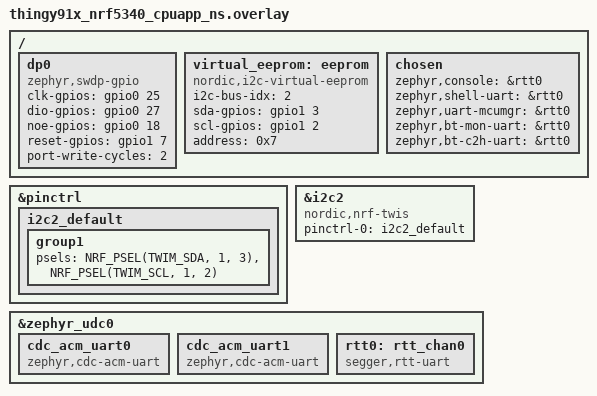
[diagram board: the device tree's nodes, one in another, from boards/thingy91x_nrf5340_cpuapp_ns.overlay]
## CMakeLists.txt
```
#
# Copyright (c) 2020 Nordic Semiconductor
#
# SPDX-License-Identifier: LicenseRef-Nordic-5-Clause
#

cmake_minimum_required(VERSION 3.20.0)

find_package(Zephyr REQUIRED HINTS $ENV{ZEPHYR_BASE})
find_package(Git)
project(NONE)

# NORDIC SDK APP START
target_sources(app PRIVATE src/main.c)
# NORDIC SDK APP END

# Generate a C header file with the readme text as a string variable
set(OUTPUT_README_HEADER_FILE "${CMAKE_BINARY_DIR}/generated/readme/readme.h")
set(INPUT_README_FILE ${CMAKE_SOURCE_DIR}/boards/${BOARD}_readme.txt)
if(NOT EXISTS ${INPUT_README_FILE})
message(WARNING "${INPUT_README_FILE} does not exist")
set(INPUT_README_FILE ${CMAKE_SOURCE_DIR}/README_TEMPLATE.txt)
endif()
file(READ ${INPUT_README_FILE} README_CONTENT)
if(GIT_FOUND)
  execute_process(
        COMMAND ${GIT_EXECUTABLE} rev-parse --short HEAD
        WORKING_DIRECTORY ${CMAKE_SOURCE_DIR}
        OUTPUT_VARIABLE GIT_HASH
        OUTPUT_STRIP_TRAILING_WHITESPACE
  )
  string(TIMESTAMP CURRENT_DATE "%Y-%m-%d")
  string(APPEND README_CONTENT "\nFirmware version: ${GIT_HASH} (${CURRENT_DATE})")
endif()
string(REPLACE "\"" "\\\"" README_CONTENT "${README_CONTENT}")
string(REPLACE "\n" "\\n\"\n\"" README_CONTENT "${README_CONTENT}")
file(WRITE ${OUTPUT_README_HEADER_FILE} "const char* file_contents = \"${README_CONTENT}\";\n\n")


# Include application events and disk files
zephyr_library_include_directories(
  src/events
  ${NRF_DIR}/samples/dap/src
  ${CMAKE_BINARY_DIR}/generated/readme
  )

# Application sources
add_subdirectory(src/disk)
add_subdirectory(src/events)
add_subdirectory(src/modules)
```

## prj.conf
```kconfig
# General
CONFIG_REBOOT=y
CONFIG_HEAP_MEM_POOL_SIZE=8192
CONFIG_SYSTEM_WORKQUEUE_STACK_SIZE=2048
CONFIG_MAIN_STACK_SIZE=2048
CONFIG_GPIO=y
CONFIG_POLL=y
CONFIG_BOOTLOADER_MCUBOOT=y
CONFIG_APP_EVENT_MANAGER=y
CONFIG_SPEED_OPTIMIZATIONS=y
CONFIG_PM_DEVICE=y

# Features
CONFIG_BRIDGE_CDC_ENABLE=y
CONFIG_BRIDGE_MSC_ENABLE=y
CONFIG_BRIDGE_BLE_ENABLE=y

 # USB
CONFIG_USB_DEVICE_STACK=y
CONFIG_USB_DEVICE_REMOTE_WAKEUP=n
CONFIG_USB_DEVICE_MANUFACTURER="Nordic Semiconductor"
CONFIG_USB_DEVICE_PRODUCT="Thingy:91 UART"
CONFIG_USB_DEVICE_VID=0x1915
CONFIG_USB_DEVICE_PID=0x9100
CONFIG_USB_DEVICE_SN="THINGY91 12PLACEHLDRS" # This is overridden at runtime
CONFIG_USB_COMPOSITE_DEVICE=y
CONFIG_USB_CDC_ACM_RINGBUF_SIZE=16384

# Disk and file system
CONFIG_DISK_ACCESS=y
CONFIG_DISK_DRIVER_RAM=y
CONFIG_DISK_RAM_VOLUME_SIZE=64
CONFIG_FILE_SYSTEM=y
CONFIG_FAT_FILESYSTEM_ELM=y
CONFIG_FS_FATFS_LFN=y

# Settings
CONFIG_FCB=y
CONFIG_SETTINGS=y
CONFIG_SETTINGS_FCB=y
CONFIG_FLASH=y
CONFIG_FLASH_PAGE_LAYOUT=y
CONFIG_FLASH_MAP=y
CONFIG_MPU_ALLOW_FLASH_WRITE=y

# Logging
CONFIG_LOG=y
CONFIG_USE_SEGGER_RTT=y
CONFIG_LOG_BACKEND_RTT=y
CONFIG_LOG_BACKEND_RTT_MODE_DROP=y

# Event logs
CONFIG_BRIDGE_LOG_MODULE_STATE_EVENT=n
CONFIG_BRIDGE_LOG_UART_DATA_EVENT=n
CONFIG_BRIDGE_LOG_CDC_DATA_EVENT=n
CONFIG_BRIDGE_LOG_BLE_DATA_EVENT=n
CONFIG_BRIDGE_LOG_BLE_CTRL_EVENT=n
CONFIG_BRIDGE_LOG_PEER_CONN_EVENT=n
CONFIG_BRIDGE_LOG_FS_EVENT=n
CONFIG_BRIDGE_LOG_POWER_DOWN_EVENT=n

 # UART
CONFIG_SERIAL=y
CONFIG_UART_INTERRUPT_DRIVEN=y
CONFIG_UART_0_INTERRUPT_DRIVEN=n
CONFIG_UART_1_INTERRUPT_DRIVEN=n
CONFIG_UART_LINE_CTRL=y
CONFIG_UART_ASYNC_API=y
CONFIG_UART_0_ASYNC=y
CONFIG_UART_1_ASYNC=y
CONFIG_UART_0_NRF_HW_ASYNC=y
CONFIG_UART_1_NRF_HW_ASYNC=y
CONFIG_UART_0_NRF_HW_ASYNC_TIMER=1
CONFIG_UART_1_NRF_HW_ASYNC_TIMER=2
CONFIG_NRFX_UARTE0=y
CONFIG_NRFX_UARTE1=y
CONFIG_NRFX_TIMER1=y
CONFIG_NRFX_TIMER2=y
CONFIG_NRFX_PPI=y

CONFIG_HW_ID_LIBRARY=y
```

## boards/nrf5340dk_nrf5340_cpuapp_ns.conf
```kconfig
CONFIG_BT=y
CONFIG_BT_DEVICE_NAME="Thingy:91 X UART"
CONFIG_BT_DEVICE_NAME_DYNAMIC=y
CONFIG_BT_PERIPHERAL=y
CONFIG_BT_PERIPHERAL_PREF_MIN_INT=6
CONFIG_BT_PERIPHERAL_PREF_MAX_INT=16
CONFIG_BT_PERIPHERAL_PREF_LATENCY=0
CONFIG_BT_PERIPHERAL_PREF_TIMEOUT=400
CONFIG_BT_BONDABLE=n

CONFIG_BT_MAX_CONN=1
CONFIG_BT_AUTO_PHY_UPDATE=y
CONFIG_BT_DATA_LEN_UPDATE=y
CONFIG_BT_HCI_ACL_FLOW_CONTROL=y
CONFIG_BT_L2CAP_TX_MTU=247
CONFIG_BT_BUF_ACL_RX_SIZE=251
CONFIG_BT_NUS=y
CONFIG_BT_GATT_CLIENT=y
CONFIG_BT_SMP=y
CONFIG_BT_BUF_ACL_TX_COUNT=10
CONFIG_BT_BUF_ACL_TX_SIZE=251
CONFIG_BT_CTLR_DATA_LENGTH_MAX=251

CONFIG_USB_DEVICE_STACK=y
CONFIG_USB_DEVICE_BOS=y
CONFIG_USB_DEVICE_REMOTE_WAKEUP=n
CONFIG_USB_MAX_POWER=250
CONFIG_CMSIS_DAP_DEVICE_VENDOR="Nordic Semiconductor"
CONFIG_CMSIS_DAP_DEVICE_NAME="nrf9160_xxaa"

CONFIG_SERIAL=y
CONFIG_DAP=y
CONFIG_NRF_TRACE_PORT=y

CONFIG_DAP_LOG_LEVEL_DBG=y
CONFIG_DP_DRIVER_LOG_LEVEL_DBG=y
CONFIG_USB_MAX_NUM_TRANSFERS=8
```

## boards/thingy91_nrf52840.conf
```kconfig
CONFIG_BT=y
CONFIG_BT_DEVICE_NAME="Thingy:91 UART"
CONFIG_BT_DEVICE_NAME_DYNAMIC=y
CONFIG_BT_PERIPHERAL=y
CONFIG_BT_PERIPHERAL_PREF_MIN_INT=6
CONFIG_BT_PERIPHERAL_PREF_MAX_INT=16
CONFIG_BT_PERIPHERAL_PREF_LATENCY=0
CONFIG_BT_PERIPHERAL_PREF_TIMEOUT=400
CONFIG_BT_BONDABLE=n
CONFIG_BT_LL_SOFTDEVICE=y
CONFIG_BT_MAX_CONN=1
CONFIG_BT_AUTO_PHY_UPDATE=y
CONFIG_BT_DATA_LEN_UPDATE=y
CONFIG_BT_HCI_ACL_FLOW_CONTROL=y
CONFIG_BT_L2CAP_TX_MTU=247
CONFIG_BT_BUF_ACL_RX_SIZE=251
CONFIG_BT_NUS=y
CONFIG_BT_GATT_CLIENT=y
CONFIG_BT_SMP=y
CONFIG_BT_CTLR=y
CONFIG_BT_CTLR_RX_BUFFERS=10
CONFIG_BT_BUF_ACL_TX_COUNT=10
CONFIG_BT_BUF_ACL_TX_SIZE=251
CONFIG_BT_CTLR_DATA_LENGTH_MAX=251

CONFIG_USB_MAX_NUM_TRANSFERS=8
CONFIG_USB_DEVICE_STACK=y
CONFIG_USB_DEVICE_BOS=y
CONFIG_USB_DEVICE_REMOTE_WAKEUP=n
CONFIG_USB_MAX_POWER=250
CONFIG_CMSIS_DAP_DEVICE_VENDOR="Nordic Semiconductor"
CONFIG_CMSIS_DAP_DEVICE_NAME="nrf9160_xxaa"
CONFIG_SERIAL=y
CONFIG_DAP=y
```

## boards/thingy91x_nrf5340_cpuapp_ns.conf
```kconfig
CONFIG_BT=y
CONFIG_BT_DEVICE_NAME="Thingy:91 X UART"
CONFIG_BT_DEVICE_NAME_DYNAMIC=y
CONFIG_BT_PERIPHERAL=y
CONFIG_BT_PERIPHERAL_PREF_MIN_INT=6
CONFIG_BT_PERIPHERAL_PREF_MAX_INT=16
CONFIG_BT_PERIPHERAL_PREF_LATENCY=0
CONFIG_BT_PERIPHERAL_PREF_TIMEOUT=400
CONFIG_BT_BONDABLE=n

CONFIG_BT_MAX_CONN=1
CONFIG_BT_AUTO_PHY_UPDATE=y
CONFIG_BT_DATA_LEN_UPDATE=y
CONFIG_BT_HCI_ACL_FLOW_CONTROL=y
CONFIG_BT_L2CAP_TX_MTU=247
CONFIG_BT_BUF_ACL_RX_SIZE=251
CONFIG_BT_NUS=y
CONFIG_BT_GATT_CLIENT=y
CONFIG_BT_SMP=y
CONFIG_BT_BUF_ACL_TX_COUNT=10
CONFIG_BT_BUF_ACL_TX_SIZE=251
CONFIG_BT_CTLR_DATA_LENGTH_MAX=251

CONFIG_USB_MAX_NUM_TRANSFERS=8
CONFIG_USB_DEVICE_STACK=y
CONFIG_USB_DEVICE_BOS=y
CONFIG_USB_DEVICE_REMOTE_WAKEUP=n
CONFIG_USB_MAX_POWER=250
CONFIG_USB_DEVICE_PRODUCT="Thingy:91 X UART"
CONFIG_CMSIS_DAP_DEVICE_VENDOR="Nordic Semiconductor"
CONFIG_CMSIS_DAP_DEVICE_NAME="nrf9160_xxaa"
CONFIG_SERIAL=y
CONFIG_DAP=y

CONFIG_I2C=y
CONFIG_I2C_VIRTUAL_EEPROM_DRIVER=y
CONFIG_I2C_VIRTUAL_EEPROM_DRIVER_LOG_LEVEL_DBG=y
```

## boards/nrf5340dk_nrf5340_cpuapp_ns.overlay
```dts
/*
 * Copyright (c) 2023 Nordic Semiconductor ASA
 *
 * SPDX-License-Identifier: Apache-2.0
 */

&uart1 {
	status = "okay";
	current-speed = <115200>;
	pinctrl-0 = <&uart1_default>;
	pinctrl-1 = <&uart1_sleep>;
	pinctrl-names = "default", "sleep";
};

 
 / {
	dp0 {
		compatible = "zephyr,swdp-gpio";
		status = "okay";
		clk-gpios = <&gpio0 19 GPIO_ACTIVE_HIGH>;
		dio-gpios = <&gpio0 20 GPIO_ACTIVE_HIGH>;
		noe-gpios = <&gpio0 21 GPIO_ACTIVE_HIGH>;
		reset-gpios = <&gpio0 22 GPIO_ACTIVE_HIGH>;
		port-write-cycles = <2>;
	};
};


&zephyr_udc0 {
	cdc_acm_uart0: cdc_acm_uart0 {
		compatible = "zephyr,cdc-acm-uart";
	};

	cdc_acm_uart1: cdc_acm_uart1 {
		compatible = "zephyr,cdc-acm-uart";
	};

	rtt0: rtt_chan0 {
		compatible = "segger,rtt-uart";
		status = "okay";
	};
};

/ {
	chosen {
		zephyr,console = &rtt0;
		zephyr,shell-uart = &rtt0;
		zephyr,uart-mcumgr = &rtt0;
		zephyr,bt-mon-uart = &rtt0;
		zephyr,bt-c2h-uart = &rtt0;
	};
};
```

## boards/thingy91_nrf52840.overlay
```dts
/*
 * Copyright (c) 2023 Nordic Semiconductor ASA
 *
 * SPDX-License-Identifier: Apache-2.0
 */

 
/ {
	dp0 {
		compatible = "zephyr,swdp-gpio";
		status = "okay";
		clk-gpios = <&gpio1 5 GPIO_ACTIVE_HIGH>;
		dio-gpios = <&gpio0 14 GPIO_ACTIVE_HIGH>;
		noe-gpios = <&gpio0 17 GPIO_ACTIVE_HIGH>;
		port-write-cycles = <2>;
	};
};

&zephyr_udc0 {
	cdc_acm_uart0: cdc_acm_uart0 {
		compatible = "zephyr,cdc-acm-uart";
	};

	cdc_acm_uart1: cdc_acm_uart1 {
		compatible = "zephyr,cdc-acm-uart";
	};

	rtt0: rtt_chan0 {
		compatible = "segger,rtt-uart";
		status = "okay";
	};
};

/ {
	chosen {
		zephyr,console = &rtt0;
		zephyr,shell-uart = &rtt0;
		zephyr,uart-mcumgr = &rtt0;
		zephyr,bt-mon-uart = &rtt0;
		zephyr,bt-c2h-uart = &rtt0;
	};
};
```

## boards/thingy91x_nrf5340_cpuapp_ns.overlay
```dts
/*
 * Copyright (c) 2023 Nordic Semiconductor ASA
 *
 * SPDX-License-Identifier: Apache-2.0
 */

 
 / {
	dp0 {
		compatible = "zephyr,swdp-gpio";
		status = "okay";
		clk-gpios = <&gpio0 25 GPIO_ACTIVE_HIGH>;
		dio-gpios = <&gpio0 27 GPIO_ACTIVE_HIGH>;
		noe-gpios = <&gpio0 18 GPIO_ACTIVE_HIGH>;
		reset-gpios = <&gpio1 7 GPIO_ACTIVE_HIGH>;
		port-write-cycles = <2>;
	};

	virtual_eeprom: eeprom {
		compatible = "nordic,i2c-virtual-eeprom";
		status = "okay";
		i2c-bus-idx = <2>;
		sda-gpios = <&gpio1 3 GPIO_ACTIVE_HIGH>;
		scl-gpios = <&gpio1 2 GPIO_ACTIVE_HIGH>;
		address = <0x7>;
	};
};

&pinctrl {
	i2c2_default: i2c2_default {
		group1 {
			psels = <NRF_PSEL(TWIM_SDA, 1, 3)>,
				<NRF_PSEL(TWIM_SCL, 1, 2)>;
		};
	};
};

&i2c2 {
	compatible = "nordic,nrf-twis";
	status = "okay";
	pinctrl-0 = <&i2c2_default>;
};


&zephyr_udc0 {
	cdc_acm_uart0: cdc_acm_uart0 {
		compatible = "zephyr,cdc-acm-uart";
	};

	cdc_acm_uart1: cdc_acm_uart1 {
		compatible = "zephyr,cdc-acm-uart";
	};

	rtt0: rtt_chan0 {
		compatible = "segger,rtt-uart";
		status = "okay";
	};
};

/ {
	chosen {
		zephyr,console = &rtt0;
		zephyr,shell-uart = &rtt0;
		zephyr,uart-mcumgr = &rtt0;
		zephyr,bt-mon-uart = &rtt0;
		zephyr,bt-c2h-uart = &rtt0;
	};
};
```

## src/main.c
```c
/*
 * Copyright (c) 2020 Nordic Semiconductor ASA
 *
 * SPDX-License-Identifier: LicenseRef-Nordic-5-Clause
 */

#include <zephyr/kernel.h>

#include <app_event_manager.h>
#include <hw_id.h>

#define MODULE main
#include "module_state_event.h"

#include <zephyr/logging/log.h>
LOG_MODULE_REGISTER(MODULE);

static uint8_t usb_serial_str[] = "THINGY91_12PLACEHLDRS";

/* Overriding weak function to set iSerialNumber at runtime. */
uint8_t *usb_update_sn_string_descriptor(void)
{
#if defined(CONFIG_SOC_SERIES_NRF52X)
	snprintk(usb_serial_str, sizeof(usb_serial_str), "THINGY91_%04X%08X",
				(uint32_t)(NRF_FICR->DEVICEADDR[1] & 0x0000FFFF)|0x0000C000,
				(uint32_t)NRF_FICR->DEVICEADDR[0]);
#else
	char buf[HW_ID_LEN] = {0};
	if (!hw_id_get(buf, ARRAY_SIZE(buf))) {
		snprintk(usb_serial_str, sizeof(usb_serial_str), "THINGY91_%s", buf);
	}
#endif
	return usb_serial_str;
}

int main(void)
{
	if (app_event_manager_init()) {
		LOG_ERR("Application Event Manager not initialized");
	} else {
		module_set_state(MODULE_STATE_READY);
	}
	return 0;
}
```
